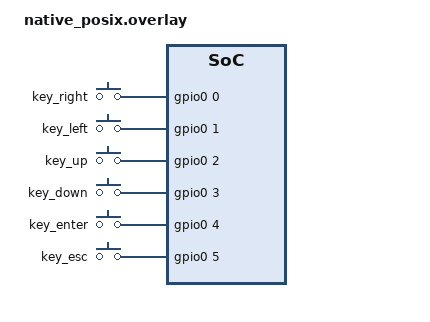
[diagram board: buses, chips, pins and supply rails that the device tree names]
/*
 * Copyright (c) 2023, Fabian Blatz <fabianblatz@gmail.com>
 *
 * SPDX-License-Identifier: Apache-2.0
 */
#include <zephyr/dt-bindings/lvgl/lvgl.h>
#include <zephyr/dt-bindings/input/input-event-codes.h>

&sdl_dc {
	compatible = "zephyr,sdl-dc";
	height = <272>;
	width = <480>;
};

/ {
	keys: keys {
		compatible = "gpio-keys";

		key_right: key_right {
			gpios = <&gpio0 0 GPIO_ACTIVE_HIGH>;
			zephyr,code = <INPUT_KEY_RIGHT>;
		};

		key_left: key_left {
			gpios = <&gpio0 1 GPIO_ACTIVE_HIGH>;
			zephyr,code = <INPUT_KEY_LEFT>;
		};

		key_up: key_up {
			gpios = <&gpio0 2 GPIO_ACTIVE_HIGH>;
			zephyr,code = <INPUT_KEY_UP>;
		};

		key_down: key_down {
			gpios = <&gpio0 3 GPIO_ACTIVE_HIGH>;
			zephyr,code = <INPUT_KEY_DOWN>;
		};

		key_enter: key_enter {
			gpios = <&gpio0 4 GPIO_ACTIVE_HIGH>;
			zephyr,code = <INPUT_KEY_ENTER>;
		};

		key_esc: key_esc {
			gpios = <&gpio0 5 GPIO_ACTIVE_HIGH>;
			zephyr,code = <INPUT_KEY_ESC>;
		};
	};

	lvgl_keypad {
		compatible = "zephyr,lvgl-keypad-input";
		input = <&keys>;
		input-codes = <INPUT_KEY_RIGHT INPUT_KEY_LEFT INPUT_KEY_UP INPUT_KEY_DOWN INPUT_KEY_ENTER INPUT_KEY_ESC>;
		lvgl-codes = <LV_KEY_RIGHT LV_KEY_LEFT LV_KEY_UP LV_KEY_DOWN LV_KEY_ENTER LV_KEY_ESC>;
	};
};

&gpio0 {
	ngpios = <6>;

	sdl_gpio {
		status = "okay";
		compatible = "zephyr,gpio-emul-sdl";
		scancodes = <79 80 82 81 40 41>;
	};
};
